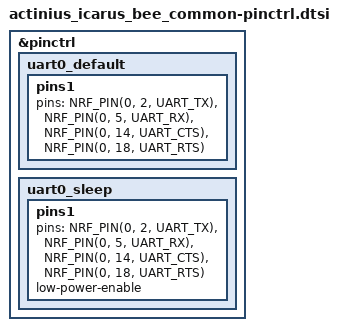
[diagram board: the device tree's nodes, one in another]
/*
 * Copyright (c) 2021 Nordic Semiconductor ASA
 * SPDX-License-Identifier: Apache-2.0
 */

&pinctrl {
	uart0_default: uart0_default {
		pins1 {
			pins = <NRF_PIN(0, 2, UART_TX)>,
			       <NRF_PIN(0, 5, UART_RX)>,
			       <NRF_PIN(0, 14, UART_CTS)>,
			       <NRF_PIN(0, 18, UART_RTS)>;
		};
	};

	uart0_sleep: uart0_sleep {
		pins1 {
			pins = <NRF_PIN(0, 2, UART_TX)>,
			       <NRF_PIN(0, 5, UART_RX)>,
			       <NRF_PIN(0, 14, UART_CTS)>,
			       <NRF_PIN(0, 18, UART_RTS)>;
			low-power-enable;
		};
	};

};
